# LPC15xx register map
File version: 0.7
CPU: CM3 r2p1, little endian, no MPU, no FPU, 3 interrupt priority bits
Registers are 32-bit, read-write, reset 0x0 unless marked. A register's access mark holds for its fields unless they carry their own. Offsets are from the block's base; [hi:lo] are bit positions; {n}, {i} and the like mark numbered series; 'fields as' and 'values as' point back to an identical list.

## SYSCON — System configuration (SYSCON)
Base 0x40074000
0x00 SYSMEMREMAP reset 0x2 — System memory remap
  [1:0] MAP
0x14 SYSTCKCAL — System tick counter calibration
  [25:0] CAL — System tick timer calibration value
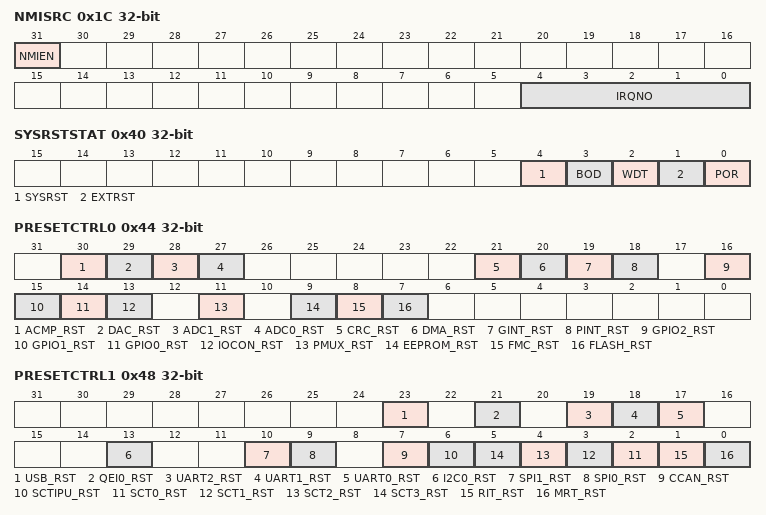
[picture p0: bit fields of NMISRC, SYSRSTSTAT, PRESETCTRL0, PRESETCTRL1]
0x1C NMISRC — NMI Source Control
  [31] NMIEN — Write a 1 to this bit to enable the Non-Maskable Interrupt (NMI) source selected by bits 4:0.
  [4:0] IRQNO — The IRQ number of the interrupt that acts as the Non-Maskable Interrupt (NMI) if bit 31 is 1. See Table 3 for the list of interrupt sources and their IRQ numbers.
0x40 SYSRSTSTAT — System reset status register
  [4] SYSRST — Status of the software system reset
    0=NO_SYSTEM_RESET_DETE (No System reset detected); 1=SYSTEM_RESET_DETECTE (System reset detected. Writing a one clears this reset.)
  [3] BOD — Status of the Brown-out detect reset
    0=NO_BOD_RESET_DETECTE (No BOD reset detected); 1=BOD_RESET_DETECTED_ (BOD reset detected. Writing a one clears this reset.)
  [2] WDT — Status of the Watchdog reset
    0=NO_WDT_RESET_DETECTE (No WDT reset detected); 1=WDT_RESET_DETECTED_ (WDT reset detected. Writing a one clears this reset.)
  [1] EXTRST — Status of the external RESET pin. External reset status.
    0=NO_RESET_EVENT_DETEC (No reset event detected.); 1=RESET_DETECTED_WRIT (Reset detected. Writing a one clears this reset.)
  [0] POR — POR reset status
    0=NO_POR_DETECTED; 1=POR_DETECTED_WRITIN (POR detected. Writing a one clears this reset.)
0x44 PRESETCTRL0 — Peripheral reset control 0
  [30] ACMP_RST — Analog Comparator (ACMP) reset control for all four 4 comparators in the analog comparator block.
    0=CLEAR_CMP_RESET_; 1=ASSERT_CMP_RESET_
  [29] DAC_RST — DAC reset control
    0=CLEAR_DAC_RESET_; 1=ASSERT_DAC_RESET_
  [28] ADC1_RST — ADC1 reset control
    0=CLEAR_ADC1_RESET_; 1=ASSERT_ADC1_RESET_
  [27] ADC0_RST — ADC0 reset control
    0=CLEAR_ADC0_RESET_; 1=ASSERT_ADC0_RESET_
  [21] CRC_RST — CRC generator reset control
    0=CLEAR_CRC_RESET_; 1=ASSERT_CRC_RESET_
  [20] DMA_RST — DMA reset control
    0=CLEAR_DMA_RESET_; 1=ASSERT_DMA_RESET_
  [19] GINT_RST — Grouped interrupt (GINT) reset control
    0=CLEAR_GINT_RESET_; 1=ASSERT_GINT_RESET_
  [18] PINT_RST — Pin interrupt (PINT) reset control
    0=CLEAR_PINT_RESET_; 1=ASSERT_PINT_RESET_
  [16] GPIO2_RST — GPIO2 reset control
    0=CLEAR_GPIO2_RESET_; 1=ASSERT_GPIO2_RESET_
  [15] GPIO1_RST — GPIO1 reset control
    0=CLEAR_GPIO1_RESET_; 1=ASSERT_GPIO1_RESET_
  [14] GPIO0_RST — GPIO0 reset control
    0=CLEAR_GPIO0_RESET_; 1=ASSERT_GPIO0_RESET_
  [13] IOCON_RST — IOCON reset control
    0=CLEAR_IOCON_RESET_; 1=ASSERT_IOCON_RESET_
  [11] PMUX_RST — Pin mux reset control
    0=CLEAR_PIN_MUX_RESET_; 1=ASSERT_PIN_MUX_RESET
  [9] EEPROM_RST — EEPROM reset control
    0=CLEAR_EEPROM_RESET_; 1=ASSERT_EEPROM_RESET_
  [8] FMC_RST — FMC reset control FMC? Is this the flash controller?
    0=CLEAR_FMC_RESET_; 1=ASSERT_FMC_RESET_
  [7] FLASH_RST — Flash reset control
    0=CLEAR_FLASH_RESET_; 1=ASSERT_FLASH_RESET_
0x48 PRESETCTRL1 — Peripheral reset control 1
  [23] USB_RST — USB reset control
    0=CLEAR_USB_RESET_; 1=ASSERT_USB_RESET_
  [21] QEI0_RST — QEI0 reset control
    0=CLEAR_QEI0_RESET_; 1=ASSERT_QEI0_RESET_
  [19] UART2_RST — UART2 reset control
    0=CLEAR_UART2_RESET_; 1=ASSERT_UART2_RESET_
  [18] UART1_RST — UART1 reset control
    0=CLEAR_UART1_RESET_; 1=ASSERT_UART1_RESET_
  [17] UART0_RST — UART0 reset control
    0=CLEAR_UART0_RESET_; 1=ASSERT_UART0_RESET_
  [13] I2C0_RST — I2C0 reset control
    0=CLEAR_I2C0_RESET_; 1=ASSERT_I2C0_RESET_
  [10] SPI1_RST — SPI1 reset control
    0=CLEAR_SPI1_RESET_; 1=ASSERT_SPI1_RESET_
  [9] SPI0_RST — SPI0 reset control
    0=CLEAR_SPI0_RESET_; 1=ASSERT_SPI0_RESET_
  [7] CCAN_RST — CCAN reset control
    0=CLEAR_CCAN_RESET_; 1=ASSERT_CCAN_RESET_
  [6] SCTIPU_RST — State configurable timer IPU (SCTIPU) reset control
    0=CLEAR_SCTIPU_RESET_; 1=ASSERT_SCTIPU_RESET_
  [n+2] SCT{n}_RST (n=0..3) — State configurable timer {n} (SCT{n}) reset control
    0=CLEAR_SCT{n}_RESET_; 1=ASSERT_SCT{n}_RESET_
  [1] RIT_RST — Repetitive interrupt timer (RIT) reset control
    0=CLEAR_RIT_RESET_; 1=ASSERT_RIT_RESET_
  [0] MRT_RST — Multi-rate timer (MRT) reset control
    0=CLEAR_MRT_RESET_; 1=ASSERT_MRT_RESET_
0x4C PIOPORCAP0 ro reset not defined — POR captured PIO status 0
  [31:0] PIOSTAT — State of PIO0_31 through PIO0_0 at power-on reset
0x50 PIOPORCAP1 ro reset not defined — POR captured PIO status 1
  [31:0] PIOSTAT — State of PIO1_31 through PIO1_0 at power-on reset
0x54 PIOPORCAP2 ro reset not defined — POR captured PIO status 2
  [11:0] PIOSTAT — State of PIO2_11 through PIO2_0 at power-on reset
0x80 MAINCLKSELA — Main clock source select A
  [1:0] SEL — Clock source for main clock source selector A
    0=IRC_OSCILLATOR; 1=SYSTEM_OSCILLATOR; 2=WATCHDOG_OSCILLATOR
0x84 MAINCLKSELB — Main clock source select B
  [1:0] SEL — Clock source for main clock source selector B. Selects the clock source for the main clock.
    0=MAINCLKSELA_CLOCK_S (MAINCLKSELA. Clock source selected in MAINCLKSELA register.); 1=SYSTEM_PLL_INPUT_; 2=SYSTEM_PLL_OUTPUT_; 3=RTC_OSCILLATOR_32_KH (RTC oscillator 32 kHz output.)
0x88 USBCLKSEL reset not defined — USB clock source select
  [1:0] SEL — USB clock source.
    0=IRC_OSCILLATOR; 1=SYSTEM_OSCILLATOR; 2=USB_PLL_OUT; 3=MAIN_CLOCK
0x8C ADCASYNCCLKSEL reset not defined — ADC asynchronous clock source select
  [1:0] SEL — USB clock source.
    0=IRC_OSCILLATOR; 1=SYSTEM_PLL_OUTPUT; 2=USB_PLL_OUTPUT; 3=SCT_PLL_OUTPUT
0x94 CLKOUTSELA — CLKOUT clock source select A
  [1:0] SEL — CLKOUT clock source
    0=IRC_OSCILLATOR; 1=CRYSTAL_OSCILLATOR_ (Crystal oscillator (SYSOSC)); 2=WATCHDOG_OSCILLATOR; 3=MAIN_CLOCK
0x98 CLKOUTSELB — CLKOUT clock source select B
  [1:0] SEL — CLKOUT clock source
    0=CLKOUTSELA_CLOCK_SO (CLKOUTSELA. Clock source selected in the CLKOUTSELA register.); 1=USB_PLL_OUTPUT_; 2=SCT_PLL_OUTPUT_; 3=RTC_32_KHZ_OUTPUT_
0xA0 SYSPLLCLKSEL — System PLL clock source select
  [1:0] SEL — System PLL clock source
    0=IRC; 1=CRYSTAL_OSCILLATOR_ (Crystal Oscillator (SYSOSC))
0xA4 USBPLLCLKSEL reset not defined — USB PLL clock source select
  [1:0] SEL — USB PLL clock source
    0=IRC_THE_USB_PLL_CLO (IRC. The USB PLL clock source must be switched to system oscillator for correct USB operation.In low-speed mode IRC is ok?); 1=SYSTEM_OSCILLATOR
0xA8 SCTPLLCLKSEL reset not defined — SCT PLL clock source select
  [1:0] SEL — SCT PLL clock source
    0=IRC; 1=SYSTEM_OSCILLATOR
0xC0 SYSAHBCLKDIV reset not defined — System clock divider
  [7:0] DIV — System AHB clock divider values 0: System clock disabled. 1: Divide by 1. to 255: Divide by 255.
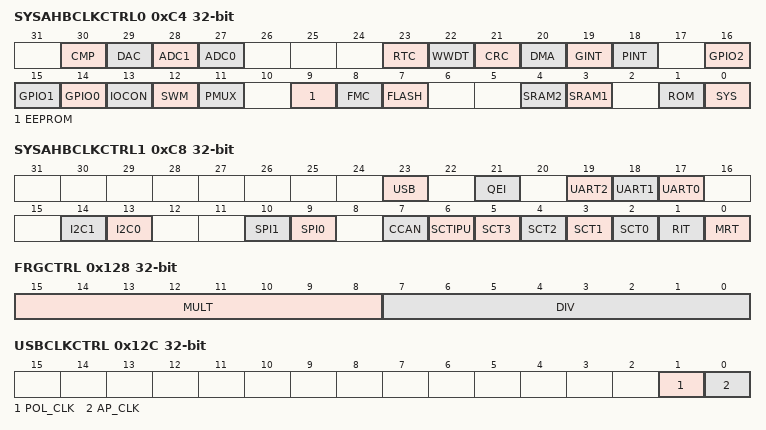
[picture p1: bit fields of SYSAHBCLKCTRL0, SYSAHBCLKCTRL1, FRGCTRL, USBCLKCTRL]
0xC4 SYSAHBCLKCTRL0 reset not defined — System clock control 0
  [30] CMP — Enables clock to analog comparator block. This is the clock to the register interface for all 4 comparators.
    0=DISABLE; 1=ENABLE
  [29] DAC — Enables clock for DAC.
    0=DISABLE; 1=ENABLE
  [28] ADC1 — Enables clock for ADC1 register interface.
    0=DISABLE; 1=ENABLE
  [27] ADC0 — Enables clock for ADC0 register interface.
    0=DISABLE; 1=ENABLE
  [23] RTC — Enables clock for RTC.
    0=DISABLE; 1=ENABLE
  [22] WWDT — Enables clock for WWDT.
    0=DISABLE; 1=ENABLE
  [21] CRC — Enables clock for CRC.
    0=DISABLE; 1=ENABLE
  [20] DMA — Enables clock for DMA.
    0=DISABLE; 1=ENABLE
  [19] GINT — Enables clock for grouped pin interrupt block.
    0=DISABLE; 1=ENABLE
  [18] PINT — Enables clock for pin interrupt block.
    0=DISABLE; 1=ENABLE
  [16] GPIO2 — Enables clock for GPIO2 port registers.
    0=DISABLE; 1=ENABLE
  [15] GPIO1 — Enables clock for GPIO1 port registers.
    0=DISABLE; 1=ENABLE
  [14] GPIO0 — Enables clock for GPIO0 port registers.
    0=DISABLE; 1=ENABLE
  [13] IOCON — Enables clock for IOCON block.
    0=DISABLE; 1=ENABLE
  [12] SWM — Enables clock for switch matrix.
    0=DISABLE; 1=ENABLE
  [11] PMUX — Enables clock for pin mux.
    0=DISABLE; 1=ENABLE
  [9] EEPROM — Enables clock for EEPROM.
    0=DISABLE; 1=ENABLE
  [8] FMC — Enables clock for flash controller.
    0=DISABLE; 1=ENABLE
  [7] FLASH — Enables clock for flash memory.
    0=DISABLE; 1=ENABLE
  [4] SRAM2 — Enables clock for SRAM2.
    0=DISABLE; 1=ENABLE
  [3] SRAM1 — Enables clock for SRAM1.
    0=DISABLE; 1=ENABLE
  [1] ROM — Enables clock for ROM.
    0=DISABLE; 1=ENABLE
  [0] SYS — Enables the clock for the AHB, the APB bridges, the Cortex-M3 core clocks, SYSCON, reset control, SRAM0, and the PMU. This bit is read-only and always reads as 1.
    1=ENABLE
0xC8 SYSAHBCLKCTRL1 — System clock control 1
  [all] fields
    0=DISABLE; 1=ENABLE
  [23] USB — Enables clock for USB register interface.
  [21] QEI — Enables clock for QEI.
  [19] UART2 — Enables clock for USART2.
  [18] UART1 — Enables clock for USART1.
  [17] UART0 — Enables clock for USART0.
  [14] I2C1 — Enables clock for I2C1.
  [13] I2C0 — Enables clock for I2C0.
  [10] SPI1 — Enables clock for SPI1.
  [9] SPI0 — Enables clock for SPI0.
  [7] CCAN — Enables clock for CCAN.
  [6] SCTIPU — Enables clock for SCTIPU.
  [n+2] SCT{n} (n=0..3) — Enables clock for SCT{n}.
  [1] RIT — Enables clock for repetitive interrupt timer.
  [0] MRT — Enables clock for multi-rate timer.
0xCC SYSTICKCLKDIV — SYSTICK clock divider
  [7:0] DIV — SYSTICK clock divider values. 0: Disable SYSTICK timer clock. 1: Divide by 1. to 255: Divide by 255.
0xD0 UARTCLKDIV — USART clock divider. Clock divider for the USART fractional baud rate generator.
  [7:0] DIV — USART fractional baud rate generator clock divider values. 0: Clock disabled. 1: Divide by 1. to 255: Divide by 255.
0xD4 IOCONCLKDIV — Peripheral clock to the IOCON block for programmable glitch filter
  [7:0] DIV — IOCON glitch filter clock divider values 0: Disable IOCONFILTR_PCLK. 1: Divide by 1. to 255: Divide by 255.
0xD8 TRACECLKDIV — ARM trace clock divider
  [7:0] DIV — ARM trace clock divider values. 0: Disable TRACE_CLK. 1: Divide by 1. to 255: Divide by 255.
0xEC USBCLKDIV reset not defined — USB clock divider
  [7:0] DIV — USB clock divider values 0: Disable USB clock. 1: Divide by 1. to 255: Divide by 255.
0xF0 ADCASYNCCLKDIV reset not defined — Asynchronous ADC clock divider
  fields as USBCLKDIV
0xF8 CLKOUTDIV — CLKOUT clock divider
  [7:0] DIV — CLKOUT clock divider values 0: Disable CLKOUT clock divider. 1: Divide by 1. to 255: Divide by 255.
0x128 FRGCTRL reset not defined — USART fractional baud rate generator control
  [15:8] MULT — Numerator of the fractional divider. MULT is equal to the programmed value.
  [7:0] DIV — Denominator of the fractional divider. DIV is equal to the programmed value +1. Always set to 0xFF to use with the fractional baud rate generator.
0x12C USBCLKCTRL reset not defined — USB clock control
  [1] POL_CLK — USB need_clock polarity for triggering the USB wake-up interrupt
    0=FALLING_EDGE_OF_THE_ (Falling edge of the USB need_clock triggers the USB wake-up (default).); 1=RISING_EDGE_OF_THE_U (Rising edge of the USB need_clock triggers the USB wake-up.)
  [0] AP_CLK — USB need_clock signal control
    0=UNDER_HARDWARE_CONTR (Under hardware control.); 1=FORCED_HIGH_
0x130 USBCLKST reset not defined — USB clock status
  [0] NEED_CLKST — USB need_clock signal status
    0=LOW; 1=HIGH
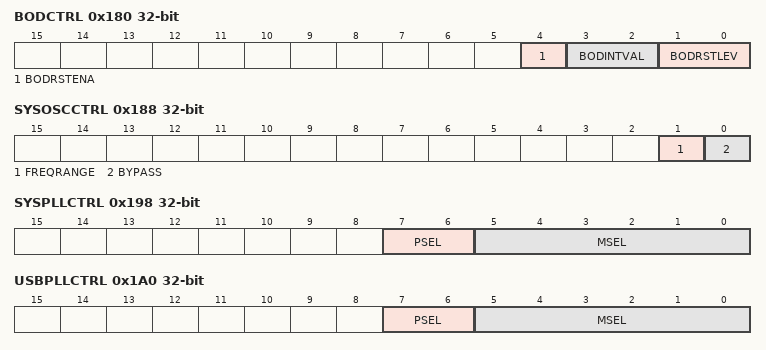
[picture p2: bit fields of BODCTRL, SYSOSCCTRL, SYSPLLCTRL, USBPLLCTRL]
0x180 BODCTRL — Brown-Out Detect
  [4] BODRSTENA — BOD reset enable
    0=DISABLE_RESET_FUNCTI (Disable reset function.); 1=ENABLE_RESET_FUNCTIO (Enable reset function.)
  [3:2] BODINTVAL — BOD interrupt level
    0=LEVEL_0_THE_INTERRU (Level 0: The interrupt assertion threshold voltage is ; the interrupt de-assertion threshold voltage is); 1=LEVEL_1_THE_INTERRU (Level 1: The interrupt assertion threshold voltage is ; the interrupt de-assertion threshold voltage is .); 2=LEVEL_2_THE_INTERRU (Level 2: The interrupt assertion threshold voltage is ; the interrupt de-assertion threshold voltage is .); 3=LEVEL_3_THE_INTERRU (Level 3: The interrupt assertion threshold voltage is ; the interrupt de-assertion threshold voltage is .)
  [1:0] BODRSTLEV — BOD reset level
    0=LEVEL_0_THE_RESET_A (Level 0: The reset assertion threshold voltage is ; the reset de-assertion threshold voltage is .); 1=LEVEL_1_THE_RESET_A (Level 1: The reset assertion threshold voltage is ; the reset de-assertion threshold voltage is .); 2=LEVEL_2_THE_RESET_A (Level 2: The reset assertion threshold voltage is ; the reset de-assertion threshold voltage is .); 3=LEVEL_3_THE_RESET_A (Level 3: The reset assertion threshold voltage is ; the reset de-assertion threshold voltage is.)
0x188 SYSOSCCTRL — System oscillator control
  [1] FREQRANGE — Determines frequency range for Low-power oscillator.
    0=1__20_MHZ_FREQUENCY (1 - 20 MHz frequency range.); 1=15__25_MHZ_FREQUENC (15 - 25 MHz frequency range)
  [0] BYPASS — Bypass system oscillator
    0=DISABLED_OSCILLATOR (Disabled. Oscillator is not bypassed.); 1=ENABLED_PLL_INPUT_ (Enabled. PLL input (sys_osc_clk) is fed directly from the XTALIN pin bypassing the oscillator. Use this mode when using an external clock source instead of the crystal oscillator.)
0x190 RTCOSCCTRL reset 0x1 — RTC oscillator control
  [0] EN — RTC 32 kHz clock enable.
    0=DISABLED_RTC_CLOCK_ (Disabled. RTC clock off.); 1=ENABLED_RTC_CLOCK_O (Enabled. RTC clock on.)
0x198 SYSPLLCTRL — System PLL control
  [7:6] PSEL — Post divider ratio P. The division ratio is 2 x P.
    0=P_EQ_1 (P = 1); 1=P_EQ_2 (P = 2); 2=P_EQ_4 (P = 4); 3=P_EQ_8 (P = 8)
  [5:0] MSEL — Feedback divider value. The division value M is the programmed MSEL value + 1. 00000: Division ratio M = 1 to 111111: Division ratio M = 64
0x19C SYSPLLSTAT ro — System PLL status
  [0] LOCK — PLL lock status
    0=PLL_NOT_LOCKED; 1=PLL_LOCKED
0x1A0 USBPLLCTRL reset not defined — USB PLL control
  [7:6] PSEL — Post divider ratio P. The division ratio is 2 x P.
    values as SYSPLLCTRL.PSEL
  [5:0] MSEL — Feedback divider value. The division value M is the programmed MSEL value + 1. 00000: Division ratio M = 1 to 111111: Division ratio M = 64.
0x1A4 USBPLLSTAT ro reset not defined — USB PLL status
  [0] LOCK — PLL lock status
    0=PLL_NOT_LOCKED; 1=PLL_LOCKED
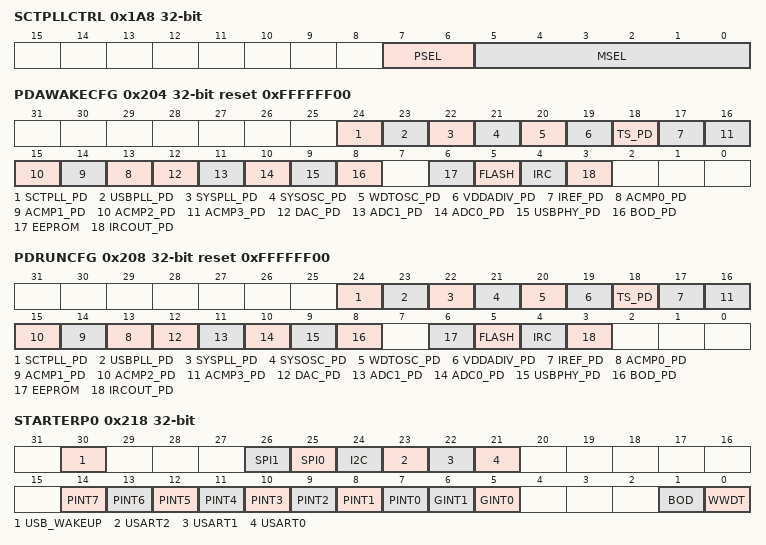
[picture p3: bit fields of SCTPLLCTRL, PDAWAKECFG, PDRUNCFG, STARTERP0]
0x1A8 SCTPLLCTRL reset not defined — SCT PLL control
  fields as USBPLLCTRL
0x1AC SCTPLLSTAT ro reset not defined — SCT PLL status
  [0] LOCK — PLL lock status
    0=PLL_NOT_LOCKED; 1=PLL_LOCKED
0x204 PDAWAKECFG reset 0xFFFFFF00 — Power-down states for wake-up from deep-sleep
  [all] fields
    0=POWERED; 1=POWERED_DOWN
  [24] SCTPLL_PD — USB PLL wake-up configuration
  [23] USBPLL_PD — USB PLL wake-up configuration
  [22] SYSPLL_PD — System PLL wake-up configuration
  [21] SYSOSC_PD — System oscillator wake-up configuration
  [20] WDTOSC_PD — Watchdog oscillator wake-up configuration.
  [19] VDDADIV_PD — VDDA divider what is this for? wake-up configuration
  [18] TS_PD — Temperature sensor wake-up configuration
  [17] IREF_PD — Internal voltage reference wake-up configuration
  [n+13] ACMP{n}_PD (n=0..3) — Analog comparator {n} wake-up configuration
  [12] DAC_PD — DAC wake-up configuration
  [11] ADC1_PD — ADC1 wake-up configuration
  [10] ADC0_PD — ADC0 wake-up configuration
  [9] USBPHY_PD — USB PHY wake-up configuration
  [8] BOD_PD — BOD wake-up configuration
  [6] EEPROM — EEPROM wake-up configuration
  [5] FLASH — Flash memory wake-up configuration
  [4] IRC — IRC oscillator wake-up configuration
  [3] IRCOUT_PD — IRC oscillator output wake-up configuration
0x208 PDRUNCFG reset 0xFFFFFF00 — Power configuration register
  [all] fields
    0=POWERED; 1=POWERED_DOWN
  [24] SCTPLL_PD — USB PLL power-down
  [23] USBPLL_PD — USB PLL power-down
  [22] SYSPLL_PD — System PLL power-down
  [21] SYSOSC_PD — System oscillator power-down
  [20] WDTOSC_PD — Watchdog oscillator power-down .
  [19] VDDADIV_PD — VDDA divider what is this for?
  [18] TS_PD — Temperature sensor power-down
  [17] IREF_PD — Internal voltage reference power-down
  [n+13] ACMP{n}_PD (n=0..3) — Analog comparator {n} power-down
  [12] DAC_PD — DAC power-down
  [11] ADC1_PD — ADC1 power-down
  [10] ADC0_PD — ADC0 power-down
  [9] USBPHY_PD — USB PHY power-down
  [8] BOD_PD — BOD power-down
  [6] EEPROM
  [5] FLASH — Flash memory
  [4] IRC — IRC oscillator
  [3] IRCOUT_PD — IRC oscillator output
0x218 STARTERP0 — Start logic 0 wake-up enable register
  [all] fields
    0=DISABLED; 1=ENABLED
  [30] USB_WAKEUP — USB need_clock signal wake-up
  [26] SPI1 — SPI1 interrupt wake-up
  [25] SPI0 — SPI0 interrupt wake-up
  [24] I2C — I2C interrupt wake-up.
  [23] USART2 — USART2 interrupt wake-up. Configure USART in synchronous slave mode or in 32 kHz mode...
  [22] USART1 — USART1 interrupt wake-up. Configure USART in synchronous slave mode or in 32 kHz mode...
  [21] USART0 — USART0 interrupt wake-up. Configure USART in synchronous slave mode or in 32 kHz mode..
  [n+7] PINT{n} (n=0..7) — GPIO pin interrupt {n} wake-up
  [6] GINT1 — Group interrupt 1 wake-up.
  [5] GINT0 — Group interrupt 0 wake-up.
  [1] BOD — BOD interrupt wake-up.
  [0] WWDT — WWDT interrupt wake-up.
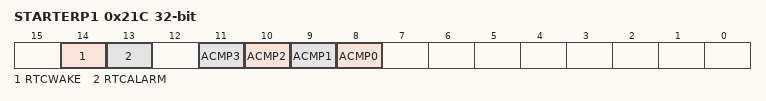
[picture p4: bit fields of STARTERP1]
0x21C STARTERP1 — Start logic 1 wake-up enable register
  [all] fields
    0=DISABLED; 1=ENABLED
  [14] RTCWAKE — RTC wake-up interrupt wake-up
  [13] RTCALARM — RTC alarm interrupt wake-up
  [n+8] ACMP{n} (n=0..3) — Analog comparator {n} interrupt wake-up
